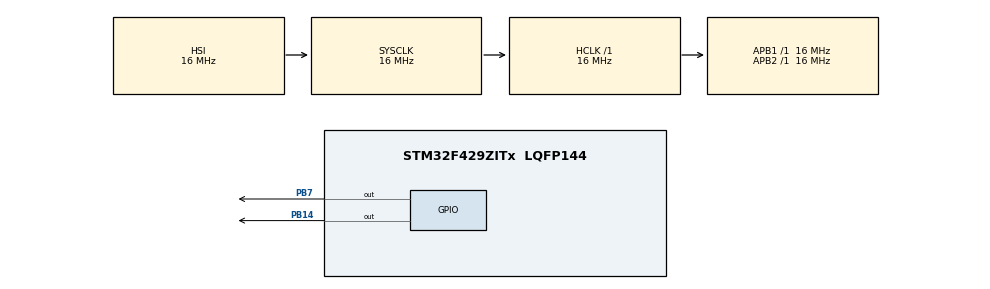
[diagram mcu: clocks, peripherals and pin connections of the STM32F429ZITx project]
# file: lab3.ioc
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FREERTOS.Queues01=myQueue01,16,uint16_t,0,Dynamic,NULL,NULL
FREERTOS.Tasks01=Task_Producer,24,128,StartTaskProducer,Default,NULL,Dynamic,NULL,NULL;Task_Consumer,8,128,StartTaskConsumer,Default,NULL,Dynamic,NULL,NULL
Mcu.Family=STM32F4
Mcu.Name=STM32F429ZITx
Mcu.Package=LQFP144
NVIC.PriorityGroup=NVIC_PRIORITYGROUP_4
PB14.Signal=GPIO_Output
PB7.Signal=GPIO_Output
ProjectManager.HeapSize=0x200
ProjectManager.StackSize=0x400
ProjectManager.TargetToolchain=STM32CubeIDE
RCC.AHBFreq_Value=16000000
RCC.APB1Freq_Value=16000000
RCC.APB2Freq_Value=16000000
RCC.CortexFreq_Value=16000000
RCC.HSE_VALUE=25000000
RCC.HSI_VALUE=16000000
RCC.LSE_VALUE=32768
RCC.SYSCLKFreq_VALUE=16000000
RCC.VCOOutputFreq_Value=192000000
VP_FREERTOS_VS_CMSIS_V2.Mode=CMSIS_V2
board=custom

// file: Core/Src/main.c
/* USER CODE BEGIN Header */
/**
  ******************************************************************************
  * @file           : main.c
  * @brief          : Main program body
  ******************************************************************************
  * @attention
  *
  * <h2><center>&copy; Copyright (c) 2020 STMicroelectronics.
  * All rights reserved.</center></h2>
  *
  * This software component is licensed by ST under BSD 3-Clause license,
  * the "License"; You may not use this file except in compliance with the
  * License. You may obtain a copy of the License at:
  *                        opensource.org/licenses/BSD-3-Clause
  *
  ******************************************************************************
  */
/* USER CODE END Header */

#include "main.h"
#include "cmsis_os.h"

/* Definitions for Task_Producer */
osThreadId_t Task_ProducerHandle;
const osThreadAttr_t Task_Producer_attributes = {
  .name = "Task_Producer",
  .priority = (osPriority_t) osPriorityNormal,
  .stack_size = 128 * 4
};
/* Definitions for Task_Consumer */
osThreadId_t Task_ConsumerHandle;
const osThreadAttr_t Task_Consumer_attributes = {
  .name = "Task_Consumer",
  .priority = (osPriority_t) osPriorityLow,
  .stack_size = 128 * 4
};
/* Definitions for myQueue01 */
osMessageQueueId_t myQueue01Handle;
const osMessageQueueAttr_t myQueue01_attributes = {
  .name = "myQueue01"
};

void SystemClock_Config(void);
static void MX_GPIO_Init(void);
void StartTaskProducer(void *argument);
void StartTaskConsumer(void *argument);

int main(void)
{

  /* MCU Configuration--------------------------------------------------------*/

  /* Reset of all peripherals, Initializes the Flash interface and the Systick. */
  HAL_Init();

  /* Configure the system clock */
  SystemClock_Config();

  /* Initialize all configured peripherals */
  MX_GPIO_Init();

  /* Init scheduler */
  osKernelInitialize();

  /* Create the queue(s) */
  /* creation of myQueue01 */
  myQueue01Handle = osMessageQueueNew (16, sizeof(uint16_t), &myQueue01_attributes);

  /* Create the thread(s) */
  /* creation of Task_Producer */
  Task_ProducerHandle = osThreadNew(StartTaskProducer, NULL, &Task_Producer_attributes);

  /* creation of Task_Consumer */
  Task_ConsumerHandle = osThreadNew(StartTaskConsumer, NULL, &Task_Consumer_attributes);

  /* Start scheduler */
  osKernelStart();

  /* We should never get here as control is now taken by the scheduler */
  /* Infinite loop */
  while (1)
  {

  }
}

void SystemClock_Config(void)
{
  RCC_OscInitTypeDef RCC_OscInitStruct = {0};
  RCC_ClkInitTypeDef RCC_ClkInitStruct = {0};

  /** Configure the main internal regulator output voltage
  */
  __HAL_RCC_PWR_CLK_ENABLE();
  __HAL_PWR_VOLTAGESCALING_CONFIG(PWR_REGULATOR_VOLTAGE_SCALE3);
  /** Initializes the CPU, AHB and APB busses clocks
  */
  RCC_OscInitStruct.OscillatorType = RCC_OSCILLATORTYPE_HSI;
  RCC_OscInitStruct.HSIState = RCC_HSI_ON;
  RCC_OscInitStruct.HSICalibrationValue = RCC_HSICALIBRATION_DEFAULT;
  RCC_OscInitStruct.PLL.PLLState = RCC_PLL_NONE;
  if (HAL_RCC_OscConfig(&RCC_OscInitStruct) != HAL_OK)
  {
    Error_Handler();
  }
  /** Initializes the CPU, AHB and APB busses clocks
  */
  RCC_ClkInitStruct.ClockType = RCC_CLOCKTYPE_HCLK|RCC_CLOCKTYPE_SYSCLK
                              |RCC_CLOCKTYPE_PCLK1|RCC_CLOCKTYPE_PCLK2;
  RCC_ClkInitStruct.SYSCLKSource = RCC_SYSCLKSOURCE_HSI;
  RCC_ClkInitStruct.AHBCLKDivider = RCC_SYSCLK_DIV1;
  RCC_ClkInitStruct.APB1CLKDivider = RCC_HCLK_DIV1;
  RCC_ClkInitStruct.APB2CLKDivider = RCC_HCLK_DIV1;

  if (HAL_RCC_ClockConfig(&RCC_ClkInitStruct, FLASH_LATENCY_0) != HAL_OK)
  {
    Error_Handler();
  }
}

static void MX_GPIO_Init(void)
{
  GPIO_InitTypeDef GPIO_InitStruct = {0};

  /* GPIO Ports Clock Enable */
  __HAL_RCC_GPIOB_CLK_ENABLE();

  /*Configure GPIO pin Output Level */
  HAL_GPIO_WritePin(GPIOB, GPIO_PIN_14|GPIO_PIN_7, GPIO_PIN_RESET);

  /*Configure GPIO pins : PB14 PB7 */
  GPIO_InitStruct.Pin = GPIO_PIN_14|GPIO_PIN_7;
  GPIO_InitStruct.Mode = GPIO_MODE_OUTPUT_PP;
  GPIO_InitStruct.Pull = GPIO_NOPULL;
  GPIO_InitStruct.Speed = GPIO_SPEED_FREQ_LOW;
  HAL_GPIO_Init(GPIOB, &GPIO_InitStruct);

}

void StartTaskProducer(void *argument)
{
  /* USER CODE BEGIN 5 */
  /* Infinite loop */
  uint8_t queue_msg = 0x00;
  for(;;)
  {
	  struct MsgPrio {
	  		uint8_t message;
	  		uint8_t priority;
	  	} tx;

	tx.message = 0x00;
	tx.priority = 0;
	tx.message++;
	osMessageQueuePut(myQueue01Handle, &tx.message, tx.priority, osWaitForever);
    osDelay(1000);
  }
  /* USER CODE END 5 */
}

void StartTaskConsumer(void *argument)
{
  /* USER CODE BEGIN StartTaskConsumer */
  /* Infinite loop */
	uint8_t buffer_get[1];
  for(;;)
  {
	  osMessageQueueGet(myQueue01Handle, &buffer_get, NULL, osWaitForever);
	  if(buffer_get[0]!=0){
		  HAL_GPIO_TogglePin(GPIOB, GPIO_PIN_7);
	  }
  }
  /* USER CODE END StartTaskConsumer */
}

void Error_Handler(void)
{
}

/************************ (C) COPYRIGHT STMicroelectronics *****END OF FILE****/
